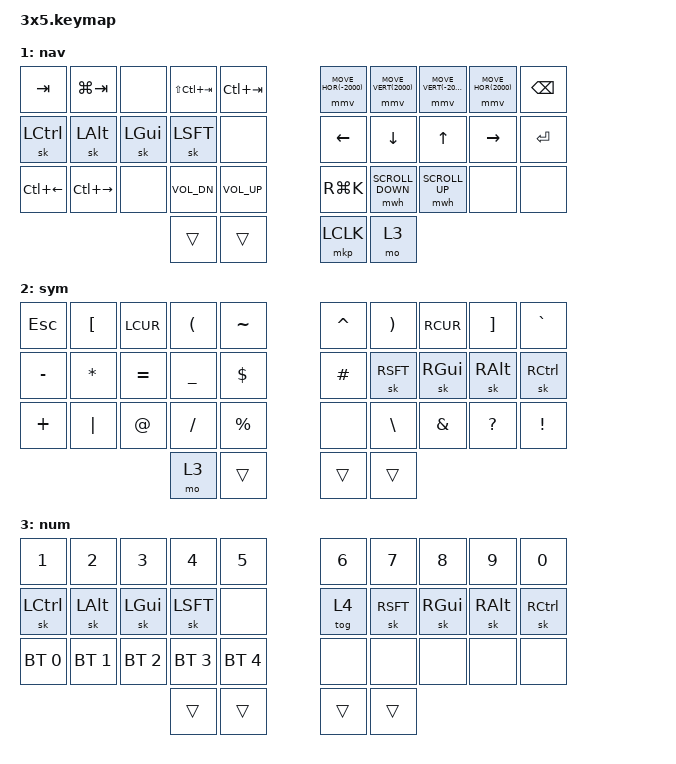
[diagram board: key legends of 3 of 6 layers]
#include <behaviors.dtsi>
#include <dt-bindings/zmk/keys.h>
#include <dt-bindings/zmk/mouse.h>
#include <dt-bindings/zmk/bt.h>

/ {
   #include "clojure.dtsi"

   combos {
      // default layer
      compatible = "zmk,combos";
      combo_default_left_vpointer {
        timeout-ms = <50>;
        key-positions = <3 13>;
        bindings = <&kp Z>;
        layers = <0>;
      };
      combo_default_left_vpointer_bot {
        timeout-ms = <50>;
        key-positions = <13 23>;
        bindings = <&kp V>;
        layers = <0>;
      };

      combo_default_right_vpointer {
        timeout-ms = <50>;
        key-positions = <6 16>;
        bindings = <&kp SCLN>;
        layers = <0>;
      };
      combo_default_right_vpointer_bot {
        timeout-ms = <50>;
        key-positions = <16 26>;
        bindings = <&kp K>;
        layers = <0>;
      };


      combo_default_left_top {
        timeout-ms = <50>;
        key-positions = <3 4>;
        bindings = <&kp LG(V)>; // paste
        layers = <0>;
      };
      combo_default_left_mid {
        timeout-ms = <50>;
        key-positions = <13 14>;
        bindings = <&kp LG(C)>; // copy
        layers = <0>;
      };
      combo_default_left_bot {
        timeout-ms = <50>;
        key-positions = <23 24>;
        bindings = <&kp LG(X)>; // cut
        layers = <0>;
      };


      // nav layer
      combo_nav_right_vpointer_bot {
        timeout-ms = <50>;
        key-positions = <16 26>;
        bindings = <&kp RG(K)>;
        layers = <1>;
      };


      combo_nav_left_pinky {
        timeout-ms = <50>;
        key-positions = <0 10>;
        bindings = <&kp LC(LEFT)>;
        layers = <1>;
      };
      combo_nav_right_pinky {
        timeout-ms = <50>;
        key-positions = <9 19>;
        bindings = <&kp RET>;
        layers = <1>;
      };


      combo_nav_hpoint_top {
        timeout-ms = <50>;
        key-positions = <3 4>;
        bindings = <&kp LG(T)>; // new tab
        layers = <1>;
      };
      combo_nav_hpoint_mid {
        timeout-ms = <50>;
        key-positions = <13 14>;
        bindings = <&kp LG(GRAVE)>; // switch win
        layers = <1>;
      };
      combo_nav_hpoint_bot {
        timeout-ms = <50>;
        key-positions = <23 24>;
        bindings = <&kp LG(N)>; // new win
        layers = <1>;
      };
      combo_nav_vmid_top {
        timeout-ms = <50>;
        key-positions = <2 12>;
        bindings = <&kp LG(W)>; // close win
        layers = <1>;
      };
      combo_nav_vpoint0_top {
        timeout-ms = <50>;
        key-positions = <3 13>;
        bindings = <&kp LG(N1)>; // first tab
        layers = <1>;
      };
      combo_nav_vpoint1_top {
        timeout-ms = <50>;
        key-positions = <4 14>;
        bindings = <&kp LG(N9)>; // last tab
        layers = <1>;
      };


      // symbol layer
      combo_sym_left_vpointer {
        timeout-ms = <50>;
        key-positions = <3 13>;
        bindings = <&kp PLUS>;
        layers = <2>;
      };
      combo_sym_left_vpointer_bot {
        timeout-ms = <50>;
        key-positions = <13 23>;
        bindings = <&kp PRCNT>;
        layers = <2>;
      };

      combo_sym_right_vpointer {
        timeout-ms = <50>;
        key-positions = <6 16>;
        bindings = <&kp EXCL>;
        layers = <2>;
      };


      // num layer
      combo_num_left_pinky {
        timeout-ms = <50>;
        key-positions = <0 10>;
        bindings = <&bt BT_SEL 0>;
        layers = <3>;
      };

      combo_num_bot {
        timeout-ms = <50>;
        key-positions = <23 24>;
        bindings = <&bt BT_CLR>;
        layers = <3>;
      };
    };
    behaviors {
      mmv {
        delay-ms = <0>;
        acceleration-exponent=<1>;
        time-to-max-speed-ms = <500>;
      };
      mwh {
        delay-ms = <0>;
        acceleration-exponent=<1>;
        time-to-max-speed-ms = <0>;
      };
    };

    macros {
    };

        keymap {
                compatible = "zmk,keymap";

                default {
// -----------------------------------------------------------------
// |  Q  |  W  |  F  |  P  |  B  |   |  J  |  L  |  U  |  Y  |  '  |
// |  A  |  R  |  S  |  T  |  G  |   |  M  |  N  |  E  |  I  |  O  |
// |  Z  |  X  |  C  |  D  |  V  |   |  K  |  H  |  ,  |  .  |  ;  |
//                   | nav | spc |   | sft | sym |
                        bindings = <
   OUTER &kp Q &kp W &kp F &kp P &kp B     &kp J &kp L &kp U      &kp Y   &kp SQT  OUTER
   OUTER &kp A &kp R &kp S &kp T &kp G     &kp M &kp N &kp E      &kp I   &kp O    OUTER
   OUTER &kp Z &kp X &kp C &kp D &kp V     &kp K &kp H &kp COMMA  &kp DOT &kp SCLN OUTER
                         &mo 1 &kp SPC     &kp RSFT &mo 2
                   >;
                sensor-bindings = <&inc_dec_kp DOWN UP &inc_dec_kp RIGHT LEFT>;

                };

                nav {
// ---------------------------------------------------------------------------
// |  tab | sapp |     | tabl | tabr |   | mlft | mdwn |  mup | mrgt | bspc |
// | ctrl |  alt | cmd | shft |      |   | left | down |   up | rght | entr |
// | spcl | spcr |     | vldn | vlup |   | cmdk | pdwn | pgup | swpl |      |
//                     |      |      |   | lclk |  num |
                        bindings = <
   &kp TAB      &kp LG(TAB)   &none     &kp LS(LC(TAB)) &kp LC(TAB)      &mmv MOVE_HOR(-2000) &mmv MOVE_VERT(2000) &mmv MOVE_VERT(-2000) &mmv MOVE_HOR(2000) &kp BSPC
   &sk LCTL     &sk LALT      &sk LGUI  &sk LSFT        &none            &kp LEFT             &kp DOWN             &kp UP                &kp RIGHT           &kp RET
   &kp LC(LEFT) &kp LC(RIGHT) &none     &kp C_VOL_DN    &kp C_VOL_UP     &kp RG(K)            &mwh SCROLL_DOWN     &mwh SCROLL_UP        &none               &none
                                                       &trans &trans     &mkp LCLK &mo 3
                      >;
                sensor-bindings = <&inc_dec_kp PG_UP PG_DN &inc_dec_kp PG_UP PG_DN>;
                };

                sym {
// -----------------------------------------------------------------
// | ESC |  [  |  {  |  (  |  ~  |   |  ^  |  )  |  }  |  ]  |  `  |
// |  -  |  *  |  =  |  _  |  $  |   |  #  | SFT | CMD | ALT | CTL |
// |  +  |  |  |  @  |  /  |  %  |   |     |  \  |  &  |  ?  |  !  |
//                   |     | ADJ |   |     |     |
                        bindings = <
   &kp ESC   &kp LBKT &kp LCUR  &kp LPAR  &kp TILDE     &kp CARET &kp RPAR &kp RCUR &kp RBKT  &kp GRAVE
   &kp MINUS &kp STAR &kp EQUAL &kp UNDER &kp DLLR      &kp HASH  &sk RSFT &sk RGUI &sk RALT  &sk RCTL
   &kp PLUS  &kp PIPE &kp AT    &kp FSLH  &kp PRCNT     &none     &kp BSLH &kp AMPS &kp QMARK &kp EXCL
                                       &mo 3 &trans     &trans &trans
                       >;
                sensor-bindings = <&inc_dec_kp C_VOL_UP C_VOL_DN &inc_dec_kp PG_UP PG_DN>;
                };

                num {
// -------------------------------------------------------------------
// |  1  |  2  |  3  |  4  |  5  |   |   6   |  7  |  8  |  9  |  0  |  
// | CTL | ALT | GUI | SFT |     |   |       | SFT | GUI | ALT | CTL |
// | bt0 | bt1 | bt2 | bt3 | bt4 |   | btclr |     |     |     |     |
//                   |     |     |   |       |     |
                        bindings = <
   &kp N1       &kp N2       &kp N3       &kp N4       &kp N5           &kp    N6 &kp N7   &kp N8   &kp N9   &kp N0
   &sk LCTL     &sk LALT     &sk LGUI     &sk LSFT     &none            &tog 4 &sk RSFT &sk RGUI &sk RALT &sk RCTL
   &bt BT_SEL 0 &bt BT_SEL 1 &bt BT_SEL 2 &bt BT_SEL 3 &bt BT_SEL 4     &none  &none    &none    &none    &none
                                                      &trans &trans     &trans &trans
                      >;
                };

                game_default {
                        bindings = <
   &kp Q &kp W &kp F &kp P &kp B     &kp J &kp L &kp U      &kp Y   &kp SQT  OUTER
   &kp A &kp R &kp S &kp T &kp G     &kp M &kp N &kp E      &kp I   &kp O    OUTER
   &kp Z &kp X &kp C &kp D &kp V     &kp K &kp H &kp COMMA  &kp DOT &kp SCLN OUTER
                   &mo 5 &kp SPC     &kp RSFT &tog 4
                      >;
                };
                game_num {
                        bindings = <
   &kp TAB  &kp N1 &kp N2 &kp N3 &sk LGUI     &kp J &kp L &kp U      &kp Y   &kp SQT  OUTER
   &kp ESC  &kp N4 &kp N5 &kp N6 &sk LALT     &kp M &kp N &kp E      &kp I   &kp O    OUTER
   &kp LSFT &kp N7 &kp N8 &kp N9 &sk LCTL     &kp K &kp H &kp COMMA  &kp DOT &kp SCLN OUTER
                           &trans &trans     &kp RSFT &mo 2
                      >;
                };

        };
};
